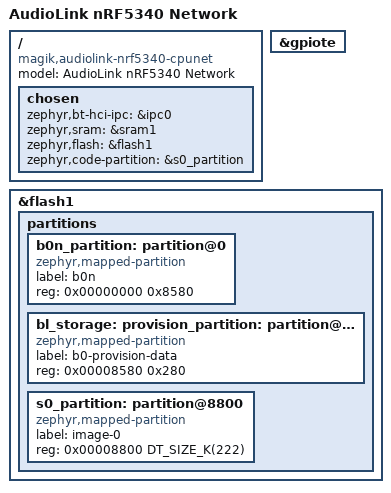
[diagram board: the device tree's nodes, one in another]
/dts-v1/;
#include <nordic/nrf5340_cpunet_qkaa.dtsi>

/ {
	model = "AudioLink nRF5340 Network";
	compatible = "magik,audiolink-nrf5340-cpunet";

	chosen {
		zephyr,bt-hci-ipc = &ipc0;
		zephyr,sram = &sram1;
		zephyr,flash = &flash1;
		zephyr,code-partition = &s0_partition;
	};
};

&gpiote {
	status = "okay";
};

/* b0n verifies and boots the controller image in s0 */
&flash1 {
	partitions {
		#address-cells = <1>;
		#size-cells = <1>;
		ranges;

		b0n_partition: partition@0 {
			compatible = "zephyr,mapped-partition";
			label = "b0n";
			reg = <0x00000000 0x8580>;
		};

		bl_storage: provision_partition: partition@8580 {
			compatible = "zephyr,mapped-partition";
			label = "b0-provision-data";
			reg = <0x00008580 0x280>;
		};

		s0_partition: partition@8800 {
			compatible = "zephyr,mapped-partition";
			label = "image-0";
			reg = <0x00008800 DT_SIZE_K(222)>;
		};
	};
};

#include <nordic/nrf5340_shared_sram_partition.dtsi>
